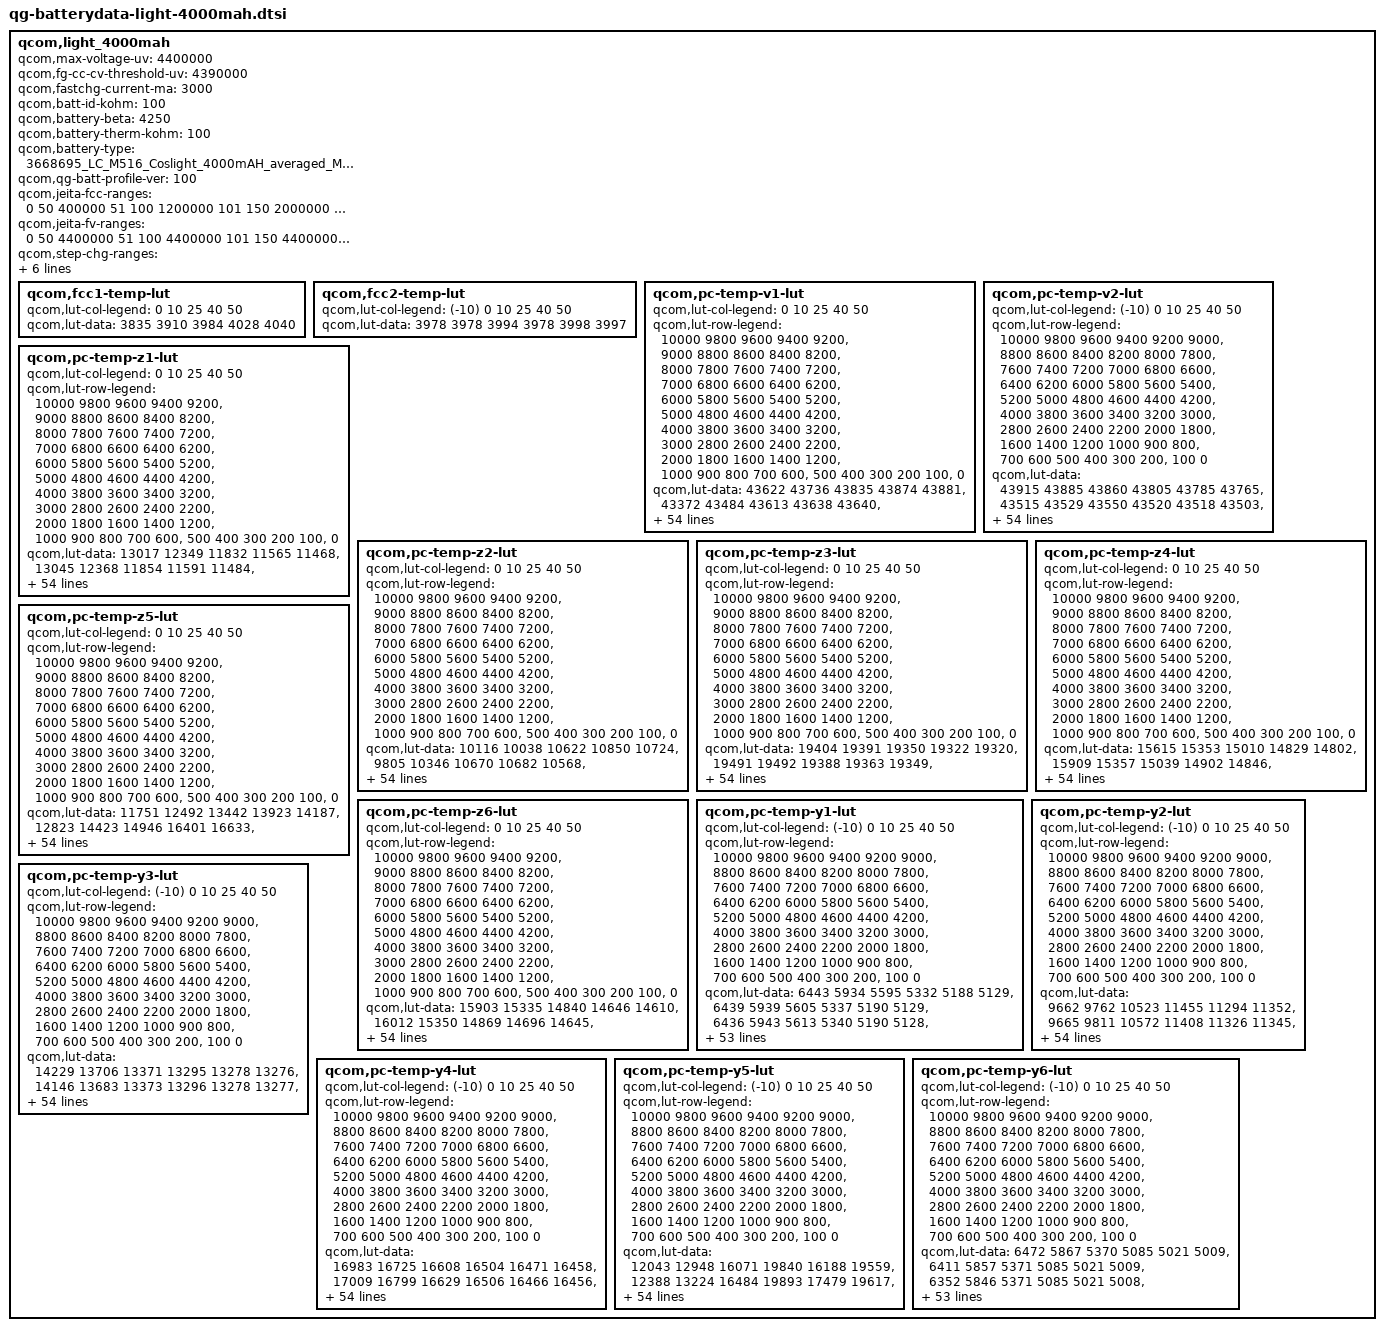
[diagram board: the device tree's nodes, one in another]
qcom,light_4000mah {
    /* 3668695_LC_M516_Coslight_4000mAH_averaged_MasterSlave_Oct30th2018 */
    qcom,max-voltage-uv = <4400000>;
    qcom,fg-cc-cv-threshold-uv = <4390000>;
    qcom,fastchg-current-ma = <3000>;
    qcom,batt-id-kohm = <100>;
    qcom,battery-beta = <4250>;
    qcom,battery-therm-kohm = <100>;
    qcom,battery-type = "3668695_LC_M516_Coslight_4000mAH_averaged_MasterSlave_Oct30th2018";
    qcom,qg-batt-profile-ver = <100>;

	qcom,jeita-fcc-ranges = <0   50   400000
                                51   100  1200000
				101  150  2000000
				151  450  3000000
				451  600  2000000>;
	qcom,jeita-fv-ranges = <0    50   4400000
				51   100  4400000
				101  150  4400000
				151  450  4400000
				451  600   4100000>;
	qcom,step-chg-ranges = <3600000  4200000  3450000
				4201000  4300000  2760000
				4301000  4350000  2070000>;

	/* COOL = 5 DegC, WARM = 45 DegC */
	qcom,jeita-soft-thresholds = <0x5316 0x20B9>;
	/* COLD = 0 DegC, HOT = 60 DegC */
	qcom,jeita-hard-thresholds = <0x58CE 0x14A6>;

	qcom,jeita-soft-hys-thresholds = <0x44C4 0x21B5>;
	qcom,jeita-soft-fcc-ua = <2000000 2000000>;
	qcom,jeita-soft-fv-uv = <4400000 4100000>;

	qcom,fcc1-temp-lut {
		qcom,lut-col-legend = <0 10 25 40 50>;
		qcom,lut-data = <3835 3910 3984 4028 4040>;
	};

	qcom,fcc2-temp-lut {
		qcom,lut-col-legend = <(-10) 0 10 25 40 50>;
		qcom,lut-data = <3978 3978 3994 3978 3998 3997>;
	};

	qcom,pc-temp-v1-lut {
		qcom,lut-col-legend = <0 10 25 40 50>;
		qcom,lut-row-legend = <10000 9800 9600 9400 9200>,
			<9000 8800 8600 8400 8200>,
			<8000 7800 7600 7400 7200>,
			<7000 6800 6600 6400 6200>,
			<6000 5800 5600 5400 5200>,
			<5000 4800 4600 4400 4200>,
			<4000 3800 3600 3400 3200>,
			<3000 2800 2600 2400 2200>,
			<2000 1800 1600 1400 1200>,
			<1000 900 800 700 600>,
			<500 400 300 200 100>,
			<0>;
		qcom,lut-data = <43622 43736 43835 43874 43881>,
			<43372 43484 43613 43638 43640>,
			<43107 43234 43369 43409 43412>,
			<42852 42990 43127 43178 43185>,
			<42616 42752 42887 42942 42952>,
			<42389 42516 42648 42704 42716>,
			<42168 42284 42412 42469 42482>,
			<41954 42059 42178 42233 42247>,
			<41749 41842 41949 42001 42015>,
			<41555 41630 41725 41771 41787>,
			<41371 41427 41505 41543 41560>,
			<41180 41232 41290 41320 41337>,
			<40976 41038 41084 41100 41116>,
			<40760 40845 40887 40889 40903>,
			<40513 40637 40689 40685 40697>,
			<40221 40387 40482 40487 40498>,
			<39976 40120 40255 40295 40306>,
			<39827 39928 40043 40111 40121>,
			<39713 39808 39883 39937 39944>,
			<39597 39697 39757 39781 39784>,
			<39474 39548 39601 39616 39618>,
			<39349 39365 39337 39395 39408>,
			<39217 39172 39055 39135 39157>,
			<39078 38954 38893 38940 38954>,
			<38936 38753 38789 38809 38808>,
			<38785 38641 38696 38697 38685>,
			<38639 38573 38602 38584 38573>,
			<38537 38514 38513 38477 38471>,
			<38461 38455 38428 38384 38378>,
			<38401 38400 38346 38300 38292>,
			<38355 38350 38275 38227 38214>,
			<38319 38302 38213 38161 38144>,
			<38290 38258 38160 38103 38080>,
			<38268 38221 38113 38050 38020>,
			<38246 38189 38073 38003 37967>,
			<38217 38153 38034 37956 37912>,
			<38180 38118 37995 37906 37851>,
			<38135 38075 37953 37852 37784>,
			<38070 38007 37891 37783 37707>,
			<37984 37908 37797 37691 37617>,
			<37886 37798 37688 37584 37515>,
			<37769 37672 37570 37465 37394>,
			<37634 37534 37436 37331 37257>,
			<37472 37378 37275 37173 37102>,
			<37327 37249 37144 37045 36982>,
			<37232 37166 37061 36971 36912>,
			<37201 37136 37042 36950 36889>,
			<37173 37112 37021 36932 36871>,
			<37140 37082 36994 36899 36836>,
			<37045 36965 36874 36738 36648>,
			<36728 36611 36532 36377 36284>,
			<36267 36139 36070 35904 35810>,
			<35682 35531 35472 35292 35196>,
			<34888 34698 34656 34453 34352>,
			<33630 33353 33374 33118 33008>,
			<30000 30000 30000 30000 30000>;
	};

	qcom,pc-temp-v2-lut {
		qcom,lut-col-legend = <(-10) 0 10 25 40 50>;
		qcom,lut-row-legend = <10000 9800 9600 9400 9200 9000>,
			<8800 8600 8400 8200 8000 7800>,
			<7600 7400 7200 7000 6800 6600>,
			<6400 6200 6000 5800 5600 5400>,
			<5200 5000 4800 4600 4400 4200>,
			<4000 3800 3600 3400 3200 3000>,
			<2800 2600 2400 2200 2000 1800>,
			<1600 1400 1200 1000 900 800>,
			<700 600 500 400 300 200>,
			<100 0>;
		qcom,lut-data = <43915 43885 43860 43805 43785 43765>,
			<43515 43529 43550 43520 43518 43503>,
			<43150 43198 43258 43249 43260 43248>,
			<42820 42896 42985 42991 43011 43001>,
			<42523 42619 42734 42748 42771 42763>,
			<42250 42361 42489 42510 42535 42527>,
			<41993 42124 42243 42273 42299 42292>,
			<41756 41899 42002 42040 42064 42058>,
			<41538 41652 41775 41811 41834 41828>,
			<41324 41366 41559 41586 41606 41601>,
			<41165 41159 41350 41366 41382 41376>,
			<41086 41082 41153 41152 41161 41157>,
			<41024 41027 40957 40942 40944 40940>,
			<40838 40875 40743 40733 40737 40732>,
			<40250 40429 40511 40524 40536 40527>,
			<39723 40000 40277 40319 40341 40331>,
			<39511 39776 40046 40116 40151 40143>,
			<39361 39602 39820 39918 39966 39963>,
			<39194 39410 39614 39740 39790 39788>,
			<39012 39200 39425 39588 39624 39623>,
			<38838 39000 39237 39424 39443 39444>,
			<38678 38817 39037 39203 39210 39211>,
			<38533 38646 38842 38958 38966 38966>,
			<38420 38496 38677 38769 38784 38784>,
			<38333 38362 38535 38625 38643 38644>,
			<38258 38254 38408 38502 38520 38522>,
			<38192 38178 38290 38391 38409 38411>,
			<38132 38118 38183 38291 38309 38310>,
			<38077 38065 38093 38201 38219 38217>,
			<38027 38020 38016 38117 38136 38131>,
			<37978 37978 37956 38041 38061 38054>,
			<37929 37939 37910 37970 37993 37985>,
			<37881 37900 37871 37906 37930 37921>,
			<37829 37859 37833 37846 37862 37851>,
			<37778 37816 37797 37794 37787 37773>,
			<37723 37770 37758 37741 37705 37684>,
			<37661 37720 37715 37679 37612 37575>,
			<37593 37666 37665 37611 37513 37458>,
			<37518 37603 37602 37539 37427 37365>,
			<37435 37530 37520 37464 37352 37288>,
			<37350 37447 37427 37381 37273 37208>,
			<37270 37348 37322 37282 37174 37111>,
			<37194 37229 37203 37165 37060 37000>,
			<37122 37097 37062 37030 36931 36871>,
			<37046 36978 36937 36918 36840 36781>,
			<36955 36898 36865 36865 36803 36750>,
			<36898 36867 36836 36849 36786 36734>,
			<36834 36833 36802 36827 36763 36710>,
			<36739 36775 36740 36784 36697 36637>,
			<36584 36655 36583 36659 36474 36398>,
			<36304 36372 36245 36299 36043 35966>,
			<35870 35897 35734 35800 35500 35421>,
			<35256 35265 35065 35169 34792 34707>,
			<34357 34387 34132 34297 33787 33712>,
			<32848 32991 32689 32911 32207 32135>,
			<28894 29872 27316 28759 27155 27106>;
	};

	qcom,pc-temp-z1-lut {
		qcom,lut-col-legend = <0 10 25 40 50>;
		qcom,lut-row-legend = <10000 9800 9600 9400 9200>,
			<9000 8800 8600 8400 8200>,
			<8000 7800 7600 7400 7200>,
			<7000 6800 6600 6400 6200>,
			<6000 5800 5600 5400 5200>,
			<5000 4800 4600 4400 4200>,
			<4000 3800 3600 3400 3200>,
			<3000 2800 2600 2400 2200>,
			<2000 1800 1600 1400 1200>,
			<1000 900 800 700 600>,
			<500 400 300 200 100>,
			<0>;
		qcom,lut-data = <13017 12349 11832 11565 11468>,
			<13045 12368 11854 11591 11484>,
			<13059 12373 11853 11590 11485>,
			<13061 12379 11846 11586 11484>,
			<13054 12383 11836 11582 11482>,
			<13040 12368 11830 11577 11479>,
			<13033 12345 11827 11572 11478>,
			<13032 12336 11825 11566 11476>,
			<13031 12335 11824 11564 11476>,
			<13021 12335 11823 11564 11476>,
			<12998 12338 11824 11563 11476>,
			<12971 12342 11833 11564 11476>,
			<12948 12341 11841 11565 11477>,
			<12924 12321 11838 11566 11478>,
			<12904 12300 11824 11565 11479>,
			<12887 12296 11815 11562 11480>,
			<12879 12295 11815 11562 11481>,
			<12883 12295 11816 11564 11482>,
			<12897 12302 11819 11566 11483>,
			<12912 12312 11828 11568 11485>,
			<12930 12322 11833 11571 11487>,
			<12943 12332 11834 11572 11488>,
			<12941 12342 11834 11572 11487>,
			<12932 12351 11834 11573 11487>,
			<12929 12357 11836 11575 11489>,
			<12942 12357 11840 11579 11493>,
			<12957 12351 11847 11582 11496>,
			<12959 12345 11856 11585 11499>,
			<12951 12344 11858 11589 11502>,
			<12943 12346 11859 11592 11505>,
			<12944 12352 11860 11595 11508>,
			<12953 12366 11860 11600 11511>,
			<12961 12376 11861 11604 11514>,
			<12977 12374 11862 11608 11518>,
			<12993 12370 11869 11610 11521>,
			<12994 12372 11875 11613 11524>,
			<12995 12379 11880 11616 11527>,
			<12999 12385 11886 11620 11529>,
			<13016 12386 11887 11624 11532>,
			<13036 12386 11887 11628 11535>,
			<13040 12387 11888 11632 11538>,
			<13028 12394 11898 11636 11541>,
			<13019 12399 11908 11639 11544>,
			<13003 12404 11910 11640 11547>,
			<13021 12408 11909 11643 11548>,
			<13037 12415 11917 11648 11550>,
			<12996 12401 11905 11646 11549>,
			<12989 12406 11904 11649 11552>,
			<13000 12411 11904 11656 11555>,
			<13021 12416 11914 11660 11558>,
			<13006 12420 11926 11661 11563>,
			<13059 12437 11932 11669 11570>,
			<13089 12473 11944 11683 11579>,
			<13098 12495 11962 11692 11592>,
			<13098 12495 11962 11692 11592>,
			<13098 12495 11962 11692 11592>;
	};

	qcom,pc-temp-z2-lut {
		qcom,lut-col-legend = <0 10 25 40 50>;
		qcom,lut-row-legend = <10000 9800 9600 9400 9200>,
			<9000 8800 8600 8400 8200>,
			<8000 7800 7600 7400 7200>,
			<7000 6800 6600 6400 6200>,
			<6000 5800 5600 5400 5200>,
			<5000 4800 4600 4400 4200>,
			<4000 3800 3600 3400 3200>,
			<3000 2800 2600 2400 2200>,
			<2000 1800 1600 1400 1200>,
			<1000 900 800 700 600>,
			<500 400 300 200 100>,
			<0>;
		qcom,lut-data = <10116 10038 10622 10850 10724>,
			<9805 10346 10670 10682 10568>,
			<10111 10436 10676 10698 10650>,
			<10255 10423 10655 10702 10687>,
			<10248 10404 10608 10679 10677>,
			<10230 10376 10567 10639 10649>,
			<10215 10343 10540 10613 10623>,
			<10204 10317 10517 10594 10590>,
			<10189 10297 10504 10583 10557>,
			<10106 10282 10495 10583 10511>,
			<9963 10274 10494 10588 10459>,
			<9923 10269 10505 10592 10438>,
			<10040 10278 10524 10596 10433>,
			<10175 10421 10545 10593 10439>,
			<10188 10587 10568 10567 10461>,
			<10129 10604 10576 10543 10491>,
			<10075 10593 10566 10529 10515>,
			<10088 10594 10547 10496 10537>,
			<10124 10537 10547 10483 10557>,
			<10147 10440 10568 10521 10573>,
			<10162 10418 10589 10569 10590>,
			<10171 10422 10606 10576 10612>,
			<10175 10423 10622 10569 10645>,
			<10176 10403 10619 10572 10706>,
			<10178 10379 10582 10603 10941>,
			<10183 10378 10556 10648 11171>,
			<10190 10389 10600 10706 11093>,
			<10197 10399 10667 10773 10803>,
			<10208 10405 10673 10785 10604>,
			<10218 10410 10643 10700 10490>,
			<10228 10417 10623 10620 10422>,
			<10236 10425 10616 10610 10413>,
			<10232 10434 10611 10610 10413>,
			<10155 10442 10613 10617 10422>,
			<10081 10450 10627 10640 10481>,
			<10152 10461 10645 10673 10562>,
			<10369 10475 10666 10713 10659>,
			<10486 10491 10693 10758 10762>,
			<10411 10510 10721 10798 10784>,
			<10300 10534 10753 10846 10752>,
			<10283 10549 10768 10877 10725>,
			<10270 10559 10767 10868 10731>,
			<10256 10556 10766 10849 10740>,
			<10299 10440 10772 10863 10730>,
			<10319 11869 10813 10829 10710>,
			<10272 12365 10850 10777 10701>,
			<10482 12353 10808 10764 10696>,
			<10529 13774 10799 10777 10724>,
			<10456 14070 10832 10855 10892>,
			<10638 13957 10981 10806 10702>,
			<10286 13624 11030 10625 10455>,
			<10007 13432 10950 10589 10420>,
			<9909 12376 10907 10500 10351>,
			<9712 11829 10819 10445 10287>,
			<9712 11829 10819 10445 10287>,
			<9712 11829 10819 10445 10287>;
	};

	qcom,pc-temp-z3-lut {
		qcom,lut-col-legend = <0 10 25 40 50>;
		qcom,lut-row-legend = <10000 9800 9600 9400 9200>,
			<9000 8800 8600 8400 8200>,
			<8000 7800 7600 7400 7200>,
			<7000 6800 6600 6400 6200>,
			<6000 5800 5600 5400 5200>,
			<5000 4800 4600 4400 4200>,
			<4000 3800 3600 3400 3200>,
			<3000 2800 2600 2400 2200>,
			<2000 1800 1600 1400 1200>,
			<1000 900 800 700 600>,
			<500 400 300 200 100>,
			<0>;
		qcom,lut-data = <19404 19391 19350 19322 19320>,
			<19491 19492 19388 19363 19349>,
			<19635 19537 19432 19380 19363>,
			<19711 19558 19449 19390 19373>,
			<19717 19568 19455 19396 19382>,
			<19720 19575 19457 19400 19389>,
			<19720 19578 19458 19401 19390>,
			<19717 19579 19458 19400 19388>,
			<19713 19578 19456 19398 19386>,
			<19649 19577 19446 19391 19377>,
			<19530 19573 19439 19383 19367>,
			<19499 19564 19438 19380 19363>,
			<19617 19554 19436 19378 19362>,
			<19744 19540 19430 19375 19359>,
			<19758 19534 19419 19369 19354>,
			<19749 19543 19415 19364 19347>,
			<19736 19556 19419 19361 19344>,
			<19704 19557 19421 19357 19343>,
			<19660 19528 19417 19353 19341>,
			<19641 19495 19409 19349 19337>,
			<19634 19497 19406 19347 19334>,
			<19630 19520 19412 19347 19333>,
			<19634 19533 19423 19350 19333>,
			<19652 19535 19421 19350 19335>,
			<19669 19537 19404 19343 19358>,
			<19679 19536 19395 19337 19383>,
			<19687 19533 19401 19351 19385>,
			<19687 19529 19412 19387 19385>,
			<19682 19527 19422 19398 19383>,
			<19675 19525 19433 19396 19377>,
			<19667 19523 19439 19392 19368>,
			<19657 19522 19436 19386 19363>,
			<19635 19521 19431 19379 19358>,
			<19539 19518 19426 19373 19352>,
			<19448 19513 19422 19367 19345>,
			<19435 19508 19418 19362 19341>,
			<19429 19504 19414 19360 19341>,
			<19426 19500 19410 19358 19342>,
			<19424 19496 19406 19356 19342>,
			<19424 19492 19403 19356 19341>,
			<19409 19488 19401 19355 19341>,
			<19306 19485 19398 19355 19344>,
			<19261 19475 19396 19354 19347>,
			<19261 19382 19393 19355 19347>,
			<19261 19352 19382 19352 19343>,
			<19261 19302 19375 19338 19326>,
			<19260 19294 19354 19332 19324>,
			<19260 19285 19356 19328 19321>,
			<19260 19271 19350 19325 19308>,
			<19260 19259 19338 19333 19332>,
			<19261 19259 19334 19344 19343>,
			<19262 19259 19335 19348 19342>,
			<19263 19260 19333 19351 19343>,
			<19266 19264 19330 19350 19345>,
			<19266 19264 19330 19350 19345>,
			<19266 19264 19330 19350 19345>;
	};

	qcom,pc-temp-z4-lut {
		qcom,lut-col-legend = <0 10 25 40 50>;
		qcom,lut-row-legend = <10000 9800 9600 9400 9200>,
			<9000 8800 8600 8400 8200>,
			<8000 7800 7600 7400 7200>,
			<7000 6800 6600 6400 6200>,
			<6000 5800 5600 5400 5200>,
			<5000 4800 4600 4400 4200>,
			<4000 3800 3600 3400 3200>,
			<3000 2800 2600 2400 2200>,
			<2000 1800 1600 1400 1200>,
			<1000 900 800 700 600>,
			<500 400 300 200 100>,
			<0>;
		qcom,lut-data = <15615 15353 15010 14829 14802>,
			<15909 15357 15039 14902 14846>,
			<15759 15323 15025 14884 14835>,
			<15570 15196 14988 14861 14819>,
			<15424 15066 14921 14832 14798>,
			<15294 14986 14865 14801 14772>,
			<15190 14922 14826 14776 14752>,
			<15101 14872 14794 14753 14733>,
			<15043 14831 14770 14737 14722>,
			<15064 14800 14750 14728 14718>,
			<15137 14778 14737 14722 14716>,
			<15136 14762 14730 14714 14712>,
			<14963 14751 14724 14707 14704>,
			<14785 14732 14717 14701 14697>,
			<14767 14716 14711 14697 14693>,
			<14798 14713 14707 14692 14690>,
			<14822 14714 14704 14687 14685>,
			<14821 14714 14699 14682 14678>,
			<14812 14712 14692 14679 14674>,
			<14802 14711 14679 14677 14672>,
			<14788 14715 14677 14675 14671>,
			<14773 14719 14743 14707 14696>,
			<14761 14729 14831 14788 14772>,
			<14749 14783 14845 14819 14803>,
			<14744 14846 14842 14818 14777>,
			<14760 14851 14837 14815 14741>,
			<14786 14828 14816 14792 14723>,
			<14793 14803 14784 14741 14710>,
			<14790 14784 14758 14714 14702>,
			<14785 14768 14735 14705 14697>,
			<14776 14753 14721 14699 14693>,
			<14763 14741 14716 14694 14688>,
			<14763 14731 14713 14691 14683>,
			<14844 14722 14711 14691 14682>,
			<14923 14715 14709 14691 14682>,
			<14924 14709 14708 14691 14683>,
			<14913 14703 14705 14692 14685>,
			<14903 14699 14702 14693 14690>,
			<14893 14699 14702 14695 14692>,
			<14884 14702 14706 14698 14694>,
			<14892 14702 14708 14700 14694>,
			<14993 14696 14700 14694 14688>,
			<15034 14697 14691 14686 14679>,
			<15016 14789 14689 14685 14682>,
			<14942 14779 14678 14675 14676>,
			<14919 14799 14658 14661 14661>,
			<14914 14802 14665 14653 14651>,
			<14910 14803 14652 14640 14634>,
			<14904 14817 14650 14633 14635>,
			<14898 14829 14672 14643 14636>,
			<14908 14841 14690 14645 14638>,
			<14919 14846 14692 14643 14641>,
			<14929 14851 14696 14643 14642>,
			<14946 14859 14703 14647 14642>,
			<14946 14859 14703 14647 14642>,
			<14946 14859 14703 14647 14642>;
	};

	qcom,pc-temp-z5-lut {
		qcom,lut-col-legend = <0 10 25 40 50>;
		qcom,lut-row-legend = <10000 9800 9600 9400 9200>,
			<9000 8800 8600 8400 8200>,
			<8000 7800 7600 7400 7200>,
			<7000 6800 6600 6400 6200>,
			<6000 5800 5600 5400 5200>,
			<5000 4800 4600 4400 4200>,
			<4000 3800 3600 3400 3200>,
			<3000 2800 2600 2400 2200>,
			<2000 1800 1600 1400 1200>,
			<1000 900 800 700 600>,
			<500 400 300 200 100>,
			<0>;
		qcom,lut-data = <11751 12492 13442 13923 14187>,
			<12823 14423 14946 16401 16633>,
			<14163 15705 16888 17488 17797>,
			<15079 16540 17957 18277 18724>,
			<15500 17287 18537 18821 19725>,
			<15791 18106 19184 19268 20617>,
			<16114 18985 20067 19843 21361>,
			<16484 19964 20957 20556 22042>,
			<16797 21171 21592 20902 22309>,
			<16317 22334 22072 20895 21637>,
			<15229 23264 22664 20871 20693>,
			<15397 23955 23662 21114 20709>,
			<18412 23966 24570 21801 21471>,
			<22119 23919 24326 22253 21914>,
			<23824 24611 23255 22175 21567>,
			<24804 26576 23061 22102 21097>,
			<25077 29371 24360 22265 21441>,
			<23133 29532 26136 22405 22807>,
			<19886 26074 27646 22731 23700>,
			<18886 22424 29868 23601 24080>,
			<19343 26487 32354 24270 24301>,
			<20300 41044 35756 24088 23492>,
			<22597 48798 39170 23404 21082>,
			<28788 47099 37273 22311 20065>,
			<35266 43651 27138 18939 20371>,
			<41944 40000 21192 16024 20928>,
			<47668 35423 21345 17573 21694>,
			<48317 32379 21833 22036 22836>,
			<46349 31386 23467 25336 23686>,
			<43707 30852 28417 27498 24256>,
			<41107 31140 33000 29347 24867>,
			<37877 32878 35951 31143 25996>,
			<33859 34685 38229 32764 27609>,
			<27067 35530 39645 33521 28381>,
			<21529 36160 40790 33930 28680>,
			<20611 36532 41276 34112 28929>,
			<20206 36861 40394 33644 29357>,
			<20031 37050 38587 32424 29882>,
			<20762 36922 36525 30878 29709>,
			<22077 36452 33683 28408 26960>,
			<21567 35846 31591 26654 24738>,
			<14378 34675 30723 26355 25894>,
			<11280 33166 30075 26210 27512>,
			<11327 24254 28554 25738 26664>,
			<11573 21071 27568 25171 24451>,
			<11593 13158 28730 22947 20684>,
			<11533 12702 20899 22299 21572>,
			<11519 12351 22472 23671 24615>,
			<11526 11890 21398 25008 20835>,
			<11579 11720 17621 22937 27595>,
			<11610 11715 16009 22510 26818>,
			<11528 11636 15438 23147 24419>,
			<11445 11564 14963 23059 22778>,
			<11346 11501 14443 20825 21754>,
			<11346 11501 14443 20825 21754>,
			<11346 11501 14443 20825 21754>;
	};

	qcom,pc-temp-z6-lut {
		qcom,lut-col-legend = <0 10 25 40 50>;
		qcom,lut-row-legend = <10000 9800 9600 9400 9200>,
			<9000 8800 8600 8400 8200>,
			<8000 7800 7600 7400 7200>,
			<7000 6800 6600 6400 6200>,
			<6000 5800 5600 5400 5200>,
			<5000 4800 4600 4400 4200>,
			<4000 3800 3600 3400 3200>,
			<3000 2800 2600 2400 2200>,
			<2000 1800 1600 1400 1200>,
			<1000 900 800 700 600>,
			<500 400 300 200 100>,
			<0>;
		qcom,lut-data = <15903 15335 14840 14646 14610>,
			<16012 15350 14869 14696 14645>,
			<15950 15335 14875 14697 14647>,
			<15863 15266 14866 14695 14648>,
			<15772 15193 14835 14686 14644>,
			<15678 15143 14805 14673 14637>,
			<15605 15101 14785 14662 14629>,
			<15547 15066 14768 14651 14621>,
			<15497 15037 14752 14641 14613>,
			<15454 15013 14737 14633 14606>,
			<15417 14994 14728 14626 14600>,
			<15384 14977 14724 14621 14596>,
			<15348 14958 14721 14617 14591>,
			<15316 14934 14714 14613 14587>,
			<15302 14920 14702 14607 14582>,
			<15295 14921 14696 14602 14577>,
			<15288 14926 14695 14598 14573>,
			<15270 14925 14695 14594 14570>,
			<15246 14912 14691 14590 14567>,
			<15233 14898 14684 14588 14564>,
			<15226 14900 14682 14586 14562>,
			<15223 14914 14714 14600 14573>,
			<15224 14932 14758 14637 14606>,
			<15231 14961 14764 14650 14620>,
			<15240 14988 14757 14648 14620>,
			<15257 14990 14749 14644 14620>,
			<15275 14981 14744 14642 14618>,
			<15279 14971 14738 14639 14612>,
			<15276 14963 14735 14636 14606>,
			<15272 14957 14732 14631 14601>,
			<15267 14952 14729 14627 14596>,
			<15259 14948 14727 14622 14591>,
			<15250 14945 14724 14618 14587>,
			<15240 14942 14722 14615 14583>,
			<15231 14940 14721 14611 14580>,
			<15229 14938 14720 14609 14578>,
			<15228 14937 14718 14609 14579>,
			<15227 14936 14716 14610 14581>,
			<15228 14938 14717 14610 14583>,
			<15230 14941 14719 14612 14583>,
			<15231 14943 14720 14613 14584>,
			<15231 14943 14717 14611 14583>,
			<15231 14943 14714 14608 14582>,
			<15233 14944 14715 14609 14583>,
			<15213 14933 14708 14604 14579>,
			<15206 14922 14699 14591 14564>,
			<15205 14919 14692 14585 14558>,
			<15204 14917 14687 14577 14550>,
			<15204 14920 14685 14573 14543>,
			<15206 14924 14691 14583 14557>,
			<15218 14934 14701 14592 14566>,
			<15232 14943 14705 14595 14569>,
			<15249 14955 14711 14599 14572>,
			<15280 14977 14720 14604 14576>,
			<15280 14977 14720 14604 14576>,
			<15280 14977 14720 14604 14576>;
	};

	qcom,pc-temp-y1-lut {
		qcom,lut-col-legend = <(-10) 0 10 25 40 50>;
		qcom,lut-row-legend = <10000 9800 9600 9400 9200 9000>,
			<8800 8600 8400 8200 8000 7800>,
			<7600 7400 7200 7000 6800 6600>,
			<6400 6200 6000 5800 5600 5400>,
			<5200 5000 4800 4600 4400 4200>,
			<4000 3800 3600 3400 3200 3000>,
			<2800 2600 2400 2200 2000 1800>,
			<1600 1400 1200 1000 900 800>,
			<700 600 500 400 300 200>,
			<100 0>;
		qcom,lut-data = <6443 5934 5595 5332 5188 5129>,
			<6439 5939 5605 5337 5190 5129>,
			<6436 5943 5613 5340 5190 5128>,
			<6435 5947 5619 5343 5190 5127>,
			<6435 5949 5623 5344 5189 5127>,
			<6435 5952 5625 5344 5188 5126>,
			<6440 5954 5621 5342 5186 5125>,
			<6446 5955 5617 5340 5184 5123>,
			<6448 5955 5616 5338 5182 5122>,
			<6447 5954 5615 5338 5180 5121>,
			<6446 5953 5614 5338 5179 5120>,
			<6442 5953 5619 5336 5177 5119>,
			<6436 5954 5627 5334 5176 5119>,
			<6438 5957 5629 5333 5175 5119>,
			<6445 5971 5630 5333 5175 5119>,
			<6450 5982 5630 5334 5175 5119>,
			<6454 5981 5631 5338 5176 5119>,
			<6458 5979 5631 5345 5179 5119>,
			<6460 5978 5631 5346 5179 5119>,
			<6459 5981 5630 5346 5178 5120>,
			<6458 5984 5629 5345 5177 5120>,
			<6463 5987 5630 5344 5177 5121>,
			<6469 5990 5632 5343 5178 5122>,
			<6467 5988 5634 5343 5179 5123>,
			<6460 5982 5636 5347 5181 5124>,
			<6452 5979 5639 5352 5184 5125>,
			<6446 5982 5643 5352 5186 5127>,
			<6440 5986 5649 5351 5189 5129>,
			<6438 5986 5649 5352 5191 5131>,
			<6446 5973 5646 5357 5192 5133>,
			<6456 5960 5643 5363 5193 5135>,
			<6452 5963 5642 5363 5196 5137>,
			<6441 5974 5643 5362 5198 5139>,
			<6433 5978 5643 5362 5201 5141>,
			<6430 5975 5642 5363 5203 5142>,
			<6428 5972 5641 5365 5204 5143>,
			<6423 5972 5641 5367 5205 5144>,
			<6419 5975 5641 5371 5206 5146>,
			<6425 5976 5645 5373 5208 5147>,
			<6444 5972 5654 5373 5211 5149>,
			<6457 5966 5658 5372 5214 5151>,
			<6453 5967 5652 5375 5215 5152>,
			<6437 5969 5641 5381 5215 5154>,
			<6439 5968 5640 5386 5218 5157>,
			<6459 5975 5651 5392 5225 5160>,
			<6468 5993 5666 5393 5226 5163>,
			<6500 6005 5667 5390 5228 5162>,
			<6486 6001 5670 5389 5227 5162>,
			<6528 5999 5667 5392 5226 5161>,
			<6518 6004 5670 5392 5228 5162>,
			<6549 6017 5682 5399 5233 5166>,
			<6532 6035 5685 5411 5239 5172>,
			<6523 6052 5703 5416 5247 5177>,
			<6568 6066 5732 5436 5259 5186>,
			<6568 6066 5732 5436 5259 5186>,
			<6568 6066 5732 5436 5259 5186>;
	};

	qcom,pc-temp-y2-lut {
		qcom,lut-col-legend = <(-10) 0 10 25 40 50>;
		qcom,lut-row-legend = <10000 9800 9600 9400 9200 9000>,
			<8800 8600 8400 8200 8000 7800>,
			<7600 7400 7200 7000 6800 6600>,
			<6400 6200 6000 5800 5600 5400>,
			<5200 5000 4800 4600 4400 4200>,
			<4000 3800 3600 3400 3200 3000>,
			<2800 2600 2400 2200 2000 1800>,
			<1600 1400 1200 1000 900 800>,
			<700 600 500 400 300 200>,
			<100 0>;
		qcom,lut-data = <9662 9762 10523 11455 11294 11352>,
			<9665 9811 10572 11408 11326 11345>,
			<9668 9862 10616 11360 11338 11327>,
			<9670 9909 10654 11314 11333 11299>,
			<9672 9944 10685 11276 11316 11264>,
			<9672 9962 10708 11248 11292 11224>,
			<9672 10011 10727 11230 11245 11164>,
			<9671 10091 10737 11217 11188 11105>,
			<9671 10129 10722 11204 11168 11090>,
			<9671 10196 10667 11192 11171 11085>,
			<9670 10228 10632 11177 11177 11083>,
			<9671 10169 10748 11152 11173 11087>,
			<9671 10080 10953 11125 11168 11095>,
			<9671 10075 11024 11129 11175 11095>,
			<9669 10147 11030 11198 11204 11082>,
			<9668 10217 11030 11277 11240 11077>,
			<9667 10264 11046 11327 11276 11128>,
			<9667 10298 11072 11371 11325 11229>,
			<9667 10243 11101 11428 11415 11344>,
			<9666 9924 11136 11512 11591 11511>,
			<9666 9707 11160 11562 11691 11607>,
			<9666 9694 11174 11527 11624 11541>,
			<9666 9687 11186 11460 11501 11431>,
			<9666 9685 11191 11444 11449 11409>,
			<9666 9685 11195 11456 11423 11434>,
			<9665 9685 11186 11472 11418 11459>,
			<9665 9684 11034 11486 11446 11473>,
			<9665 9681 10728 11500 11487 11492>,
			<9665 9678 10603 11514 11519 11524>,
			<9664 9676 10578 11531 11569 11597>,
			<9664 9674 10561 11545 11611 11643>,
			<9664 9672 10535 11560 11661 11638>,
			<9664 9670 10507 11584 11713 11626>,
			<9663 9668 10481 11591 11705 11630>,
			<9663 9667 10453 11574 11640 11664>,
			<9663 9665 10423 11549 11586 11679>,
			<9663 9664 10395 11524 11565 11624>,
			<9662 9663 10356 11494 11553 11540>,
			<9662 9662 10229 11458 11550 11488>,
			<9662 9662 9929 11414 11555 11438>,
			<9662 9661 9751 11365 11557 11399>,
			<9661 9660 9704 11312 11501 11377>,
			<9661 9660 9683 11253 11433 11368>,
			<9661 9660 9676 11175 11405 11368>,
			<9661 9659 9670 11075 11314 11269>,
			<9660 9659 9670 11038 11214 11111>,
			<9660 9659 9669 11044 11233 11088>,
			<9660 9659 9666 11055 11280 11127>,
			<9660 9659 9665 11030 11305 11149>,
			<9659 9658 9663 11039 11260 11134>,
			<9659 9658 9662 10949 11150 11063>,
			<9658 9658 9660 10828 11093 10975>,
			<9658 9657 9658 10774 11036 10878>,
			<9655 9657 9657 10690 10969 10751>,
			<9655 9657 9657 10690 10969 10751>,
			<9655 9657 9657 10690 10969 10751>;
	};

	qcom,pc-temp-y3-lut {
		qcom,lut-col-legend = <(-10) 0 10 25 40 50>;
		qcom,lut-row-legend = <10000 9800 9600 9400 9200 9000>,
			<8800 8600 8400 8200 8000 7800>,
			<7600 7400 7200 7000 6800 6600>,
			<6400 6200 6000 5800 5600 5400>,
			<5200 5000 4800 4600 4400 4200>,
			<4000 3800 3600 3400 3200 3000>,
			<2800 2600 2400 2200 2000 1800>,
			<1600 1400 1200 1000 900 800>,
			<700 600 500 400 300 200>,
			<100 0>;
		qcom,lut-data = <14229 13706 13371 13295 13278 13276>,
			<14146 13683 13373 13296 13278 13277>,
			<14066 13661 13375 13297 13279 13277>,
			<13992 13640 13376 13298 13280 13277>,
			<13927 13619 13377 13299 13281 13278>,
			<13874 13600 13378 13300 13282 13278>,
			<13839 13582 13379 13301 13282 13279>,
			<13808 13565 13379 13302 13282 13280>,
			<13758 13548 13380 13303 13283 13281>,
			<13670 13528 13387 13304 13284 13282>,
			<13618 13510 13393 13305 13285 13282>,
			<13622 13485 13385 13306 13285 13283>,
			<13632 13459 13372 13307 13285 13284>,
			<13630 13453 13367 13308 13286 13284>,
			<13603 13459 13362 13309 13289 13284>,
			<13580 13461 13360 13310 13292 13284>,
			<13575 13447 13358 13307 13291 13286>,
			<13573 13425 13354 13303 13290 13288>,
			<13574 13414 13350 13302 13290 13288>,
			<13580 13410 13345 13303 13291 13289>,
			<13584 13406 13339 13304 13291 13289>,
			<13584 13402 13334 13302 13287 13285>,
			<13582 13396 13329 13297 13281 13277>,
			<13583 13388 13325 13294 13280 13276>,
			<13593 13372 13322 13293 13279 13276>,
			<13607 13362 13319 13292 13279 13276>,
			<13621 13367 13308 13292 13279 13276>,
			<13635 13379 13293 13292 13279 13277>,
			<13653 13393 13287 13292 13279 13277>,
			<13676 13406 13285 13291 13279 13275>,
			<13701 13422 13285 13291 13279 13275>,
			<13725 13444 13288 13291 13279 13275>,
			<13750 13470 13291 13291 13280 13275>,
			<13779 13497 13297 13292 13280 13275>,
			<13812 13524 13305 13292 13280 13276>,
			<13847 13556 13314 13292 13280 13277>,
			<13884 13592 13322 13291 13279 13276>,
			<13922 13634 13331 13291 13278 13275>,
			<13961 13679 13341 13291 13278 13275>,
			<14002 13730 13351 13291 13279 13276>,
			<14044 13782 13365 13292 13280 13277>,
			<14088 13832 13386 13292 13280 13278>,
			<14135 13881 13416 13293 13280 13278>,
			<14194 13933 13451 13295 13279 13277>,
			<14260 13987 13499 13298 13281 13277>,
			<14285 13998 13517 13300 13284 13282>,
			<14279 14016 13524 13302 13287 13284>,
			<14348 14059 13569 13306 13290 13286>,
			<14406 14117 13618 13313 13291 13286>,
			<14484 14161 13663 13315 13288 13283>,
			<14548 14217 13711 13311 13285 13283>,
			<14656 14285 13804 13314 13289 13284>,
			<14784 14387 13944 13323 13294 13288>,
			<15299 14501 14107 13332 13299 13293>,
			<15299 14501 14107 13332 13299 13293>,
			<15299 14501 14107 13332 13299 13293>;
	};

	qcom,pc-temp-y4-lut {
		qcom,lut-col-legend = <(-10) 0 10 25 40 50>;
		qcom,lut-row-legend = <10000 9800 9600 9400 9200 9000>,
			<8800 8600 8400 8200 8000 7800>,
			<7600 7400 7200 7000 6800 6600>,
			<6400 6200 6000 5800 5600 5400>,
			<5200 5000 4800 4600 4400 4200>,
			<4000 3800 3600 3400 3200 3000>,
			<2800 2600 2400 2200 2000 1800>,
			<1600 1400 1200 1000 900 800>,
			<700 600 500 400 300 200>,
			<100 0>;
		qcom,lut-data = <16983 16725 16608 16504 16471 16458>,
			<17009 16799 16629 16506 16466 16456>,
			<17032 16859 16661 16507 16463 16454>,
			<17051 16904 16693 16509 16461 16453>,
			<17066 16935 16719 16511 16461 16452>,
			<17077 16948 16730 16511 16461 16452>,
			<17079 16939 16728 16512 16462 16452>,
			<17079 16918 16723 16512 16464 16453>,
			<17105 16916 16721 16513 16466 16454>,
			<17229 16950 16720 16517 16468 16456>,
			<17358 16999 16721 16520 16470 16458>,
			<17448 17164 16763 16523 16474 16460>,
			<17519 17390 16836 16525 16481 16464>,
			<17475 17390 16865 16532 16486 16468>,
			<17113 17084 16874 16556 16491 16474>,
			<16847 16850 16865 16581 16497 16481>,
			<16840 16836 16820 16597 16508 16488>,
			<16842 16830 16762 16610 16523 16495>,
			<16831 16818 16734 16622 16540 16507>,
			<16783 16786 16717 16635 16564 16531>,
			<16734 16747 16697 16642 16577 16544>,
			<16707 16702 16656 16604 16544 16521>,
			<16687 16656 16606 16528 16489 16480>,
			<16681 16635 16576 16495 16469 16464>,
			<16679 16626 16556 16483 16461 16457>,
			<16679 16621 16543 16478 16458 16454>,
			<16679 16619 16545 16478 16460 16455>,
			<16681 16619 16558 16480 16463 16457>,
			<16682 16619 16558 16482 16468 16461>,
			<16682 16620 16552 16486 16475 16469>,
			<16683 16621 16549 16490 16484 16479>,
			<16686 16620 16549 16492 16495 16490>,
			<16693 16620 16550 16494 16505 16500>,
			<16700 16624 16553 16494 16506 16502>,
			<16706 16634 16557 16495 16501 16499>,
			<16711 16646 16563 16494 16494 16495>,
			<16713 16655 16572 16490 16477 16478>,
			<16714 16663 16582 16482 16458 16456>,
			<16714 16669 16594 16479 16455 16452>,
			<16716 16676 16609 16481 16458 16456>,
			<16718 16682 16620 16484 16462 16460>,
			<16725 16685 16627 16491 16464 16461>,
			<16737 16682 16630 16500 16465 16462>,
			<16758 16659 16628 16504 16458 16452>,
			<16784 16650 16625 16506 16454 16448>,
			<16779 16649 16622 16512 16465 16462>,
			<16764 16651 16632 16517 16479 16483>,
			<16784 16674 16657 16532 16507 16514>,
			<16802 16704 16687 16556 16519 16521>,
			<16809 16729 16705 16568 16493 16481>,
			<16790 16711 16698 16531 16466 16456>,
			<16771 16687 16686 16543 16471 16459>,
			<16769 16691 16697 16568 16484 16466>,
			<16900 16709 16720 16601 16528 16510>,
			<16900 16709 16720 16601 16528 16510>,
			<16900 16709 16720 16601 16528 16510>;
	};

	qcom,pc-temp-y5-lut {
		qcom,lut-col-legend = <(-10) 0 10 25 40 50>;
		qcom,lut-row-legend = <10000 9800 9600 9400 9200 9000>,
			<8800 8600 8400 8200 8000 7800>,
			<7600 7400 7200 7000 6800 6600>,
			<6400 6200 6000 5800 5600 5400>,
			<5200 5000 4800 4600 4400 4200>,
			<4000 3800 3600 3400 3200 3000>,
			<2800 2600 2400 2200 2000 1800>,
			<1600 1400 1200 1000 900 800>,
			<700 600 500 400 300 200>,
			<100 0>;
		qcom,lut-data = <12043 12948 16071 19840 16188 19559>,
			<12388 13224 16484 19893 17479 19617>,
			<12760 13671 16943 19862 18235 19603>,
			<13123 14204 17392 19780 18587 19530>,
			<13443 14733 17776 19679 18665 19412>,
			<13682 15171 18040 19595 18600 19262>,
			<13883 16070 18194 19470 18146 19059>,
			<14044 17264 18311 19266 17433 18813>,
			<13923 17140 18615 19012 17131 18582>,
			<13020 14691 19860 18513 16984 18318>,
			<12386 12919 20715 17973 16806 18011>,
			<15106 14021 18467 17445 16222 17638>,
			<19819 16319 14776 16880 15465 17194>,
			<20378 17920 14507 16435 15368 16639>,
			<16620 19969 17819 15958 15656 15868>,
			<13804 21097 20458 15662 15833 15454>,
			<13956 20365 20688 15513 15457 15518>,
			<14390 18875 20674 15339 14944 15642>,
			<14726 17843 21121 15663 15069 15807>,
			<15023 17179 22279 18558 16366 16388>,
			<15184 16898 23218 21548 17814 17047>,
			<14606 16757 23548 23027 19173 17660>,
			<13416 16526 23773 24075 20356 18357>,
			<12945 15914 24004 24280 20651 19094>,
			<12846 14001 24258 24066 20684 20071>,
			<12810 12632 24493 23755 20565 20610>,
			<12794 12608 23157 23412 19943 20181>,
			<12768 12629 19995 23007 19018 19201>,
			<12784 12633 18383 22721 18589 18164>,
			<12989 12735 16103 22595 18376 16876>,
			<13219 12898 14887 22585 18297 16195>,
			<13339 13253 14937 23014 18551 16294>,
			<13428 13722 15129 24042 19148 16604>,
			<13540 13851 15547 24573 20016 17327>,
			<13767 13873 16583 24683 21429 19270>,
			<13990 13895 17163 24705 22159 20752>,
			<14090 14070 17253 24229 21881 21274>,
			<14168 14420 17261 22963 21302 21579>,
			<14148 14628 16744 21679 20882 21499>,
			<13829 14737 15397 20419 20568 21000>,
			<13455 14797 14587 19317 20208 20661>,
			<13333 14726 14470 18430 19618 20701>,
			<13305 14620 14583 17582 19282 20885>,
			<13473 14463 14512 17181 19206 20100>,
			<13674 13969 14374 17639 19103 18072>,
			<13982 13845 14454 17438 17875 18448>,
			<14010 14101 14260 17409 18131 17881>,
			<14302 14188 14293 17727 18628 17564>,
			<14415 14119 14471 18320 18408 17095>,
			<14651 14349 14620 19128 18744 18705>,
			<14374 14641 14503 19536 19233 20144>,
			<13909 14171 14515 18747 20647 19948>,
			<13750 14099 14512 19655 23994 22499>,
			<12448 14027 14897 20308 24959 25405>,
			<12448 14027 14897 20308 24959 25405>,
			<12448 14027 14897 20308 24959 25405>;
	};

	qcom,pc-temp-y6-lut {
		qcom,lut-col-legend = <(-10) 0 10 25 40 50>;
		qcom,lut-row-legend = <10000 9800 9600 9400 9200 9000>,
			<8800 8600 8400 8200 8000 7800>,
			<7600 7400 7200 7000 6800 6600>,
			<6400 6200 6000 5800 5600 5400>,
			<5200 5000 4800 4600 4400 4200>,
			<4000 3800 3600 3400 3200 3000>,
			<2800 2600 2400 2200 2000 1800>,
			<1600 1400 1200 1000 900 800>,
			<700 600 500 400 300 200>,
			<100 0>;
		qcom,lut-data = <6472 5867 5370 5085 5021 5009>,
			<6411 5857 5371 5085 5021 5009>,
			<6352 5846 5371 5085 5021 5008>,
			<6298 5833 5371 5085 5021 5008>,
			<6249 5819 5371 5085 5021 5009>,
			<6208 5806 5370 5086 5021 5009>,
			<6173 5792 5365 5086 5022 5009>,
			<6143 5778 5357 5086 5022 5010>,
			<6121 5760 5353 5086 5023 5011>,
			<6102 5736 5351 5087 5024 5012>,
			<6093 5722 5350 5088 5026 5013>,
			<6111 5748 5353 5089 5027 5014>,
			<6140 5791 5359 5090 5028 5016>,
			<6129 5790 5361 5092 5031 5017>,
			<6016 5715 5359 5099 5034 5019>,
			<5932 5651 5356 5105 5037 5021>,
			<5930 5639 5345 5108 5041 5024>,
			<5930 5632 5329 5111 5044 5027>,
			<5928 5622 5318 5114 5049 5032>,
			<5919 5607 5309 5118 5056 5039>,
			<5910 5593 5299 5120 5059 5042>,
			<5903 5582 5284 5107 5047 5032>,
			<5898 5572 5267 5082 5027 5015>,
			<5897 5567 5258 5072 5020 5009>,
			<5905 5566 5254 5068 5018 5008>,
			<5915 5565 5251 5067 5017 5007>,
			<5926 5571 5251 5067 5017 5007>,
			<5939 5588 5250 5068 5018 5008>,
			<5953 5603 5250 5070 5020 5010>,
			<5970 5618 5253 5072 5022 5011>,
			<5989 5635 5259 5074 5025 5014>,
			<6008 5655 5267 5075 5029 5017>,
			<6030 5680 5279 5077 5032 5020>,
			<6054 5706 5292 5079 5033 5021>,
			<6081 5736 5308 5080 5032 5021>,
			<6109 5769 5326 5081 5030 5021>,
			<6138 5803 5346 5081 5025 5015>,
			<6169 5841 5369 5080 5019 5009>,
			<6200 5881 5395 5080 5018 5008>,
			<6232 5925 5424 5082 5020 5010>,
			<6265 5969 5457 5087 5022 5012>,
			<6302 6010 5496 5092 5024 5013>,
			<6343 6048 5542 5100 5024 5014>,
			<6395 6083 5592 5107 5023 5010>,
			<6457 6124 5652 5117 5023 5009>,
			<6483 6139 5666 5124 5029 5018>,
			<6483 6153 5682 5127 5036 5025>,
			<6544 6193 5732 5137 5046 5036>,
			<6596 6247 5784 5151 5050 5038>,
			<6658 6288 5831 5157 5040 5024>,
			<6708 6329 5875 5147 5031 5017>,
			<6790 6380 5954 5165 5037 5020>,
			<6899 6464 6078 5194 5046 5026>,
			<7389 6567 6220 5226 5064 5043>,
			<7389 6567 6220 5226 5064 5043>,
			<7389 6567 6220 5226 5064 5043>;
	};

};
